# QSPI register map
Vendor: Texas Instruments
Peripheral module from a debugger description file (folder am574x).
Registers are 32-bit, access per field, reset 0x0 unless marked. A register's access mark holds for its fields unless they carry their own. Offsets are as the file gives them; lines under a group give offsets from that group; [hi:lo] are bit positions; {n}, {i} and the like mark numbered series; 'fields as' and 'values as' point back to an identical list; <NAME> marks a mode.

## QSPI
0x00 QSPI_PID ro reset not defined — Revision register
  [31:0] REVISION — IP Revision
0x10 QSPI_SYSCONFIG reset 0x28
  [3:2] IDLE_MODE rw — Configuration of the local target state management mode. By definition, target can handle read/write transaction as long as it is out of IDLE state. 0x0: Force-idle mode 0x1: No-idle mode 0x2: Smart-idle mode 0x3: Reserved.
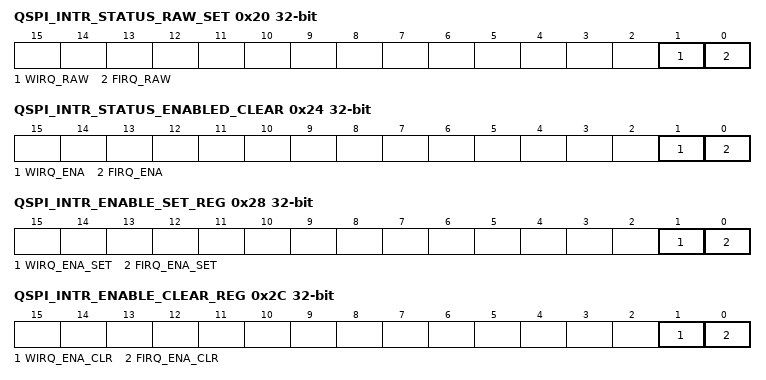
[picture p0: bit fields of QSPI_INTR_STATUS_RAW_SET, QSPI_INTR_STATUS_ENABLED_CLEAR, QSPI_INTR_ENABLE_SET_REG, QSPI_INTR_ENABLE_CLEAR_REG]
0x20 QSPI_INTR_STATUS_RAW_SET rw — This register contains raw interrupt status flags.
  [1] WIRQ_RAW — Word Interrupt Status. Read indicates the raw status.Read: . Write: .
    0=READ_INACTIVE (No interrupt); 1=READ_ACTIVE (Interrupt); 0=READ_INACTIVE (Has no effect); 1=READ_ACTIVE (Sets this raw status bit)
  [0] FIRQ_RAW — Frame Interrupt Status. Read indicates the raw status.Read: . Write: .
    0=READ_INACTIVE (No interrupt); 1=READ_ACTIVE (Interrupt); 0=Has_no_effect; 1=Sets_this_raw_status_bit
0x24 QSPI_INTR_STATUS_ENABLED_CLEAR — This register contains status flags of the enabled interrupts.
  [1] WIRQ_ENA rw — Word Interrupt Enabled Status. Read indicates enabled status.Read: . Write: .
    0=INACTIVE (No interrupt); 1=ACTIVE (Interrupt); 0=INACTIVE (Has no effect); 1=ACTIVE (Clears the word interrupt status flag. The corresponding raw status flag is also cleared.)
  [0] FIRQ_ENA rw — Frame Interrupt Enabled Status. Read indicates enabled status.Read: . Write: .
    0=INACTIVE (No interrupt); 1=ACTIVE (Interrupt); 0=INACTIVE (Has no effect); 1=ACTIVE (Clears the frame interrupt status flag. The corresponding raw status flag is also cleared.)
0x28 QSPI_INTR_ENABLE_SET_REG — This register enables the interrupts.
  [1] WIRQ_ENA_SET rw — Word interrupt enable.Read: . Write: .
    0=Disabled (Word interrupt is disabled); 1=Enabled (Word interrupt enabled); 0=Has_no_effect; 1=Enables_the_word_interrupt
  [0] FIRQ_ENA_SET rw — Frame interrupt enable.Read: . Write: .
    0=Disabled (Frame interrupt is disabled); 1=Enabled (Frame interrupt is enabled); 0=Has_no_effect; 1=Enables_the_frame_interrupt
0x2C QSPI_INTR_ENABLE_CLEAR_REG — This register disables the interrupts.
  [1] WIRQ_ENA_CLR rw — Word interrupt disable.Read: . Write: .
    0=Disabled (Word interrupt is disabled); 1=Enabled (Word interrupt is enabled); 0=Has_no_effect; 1=Clears_the_word_interrupt
  [0] FIRQ_ENA_CLR rw — Frame interrupt disable.Read: . Write: .
    0=Disabled (Frame interrupt is disabled); 1=Enabled (Frame interrupt is enabled); 0=Has_no_effect; 1=Clears_the_frame_interrupt
0x30 QSPI_INTC_EOI_REG rw — Software End-Of-Interrupt: Allows the generation of further pulses on the interrupt line, if a new interrupt event is pending, when using the pulsed output. Unused when using the level interrupt line (depending on module integration).
  [31:0] EOI_VECTOR — Number associated with the interrupt outputs. There is one interrupt output. Write 0x0 after servicing the interrupt to be able to generate another interrupt if pulse interrupts are used. Any other write value is ignored.
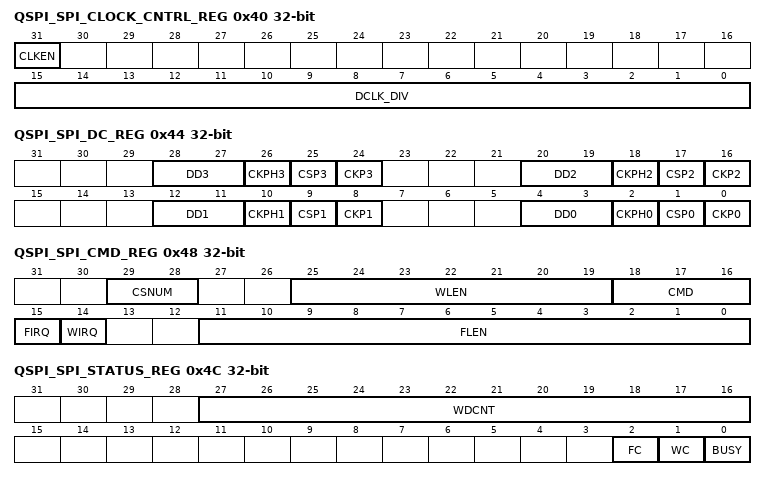
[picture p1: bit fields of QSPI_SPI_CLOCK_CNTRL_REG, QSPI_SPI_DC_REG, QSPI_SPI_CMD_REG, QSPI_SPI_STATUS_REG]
0x40 QSPI_SPI_CLOCK_CNTRL_REG — This register controls the external SPI clock generation. This register can only be written when the QSPI module is not busy, as identified by the[0] BUSY bit.
  [31] CLKEN rw — External SPI clock (qspi1_sclk) enable.
    0=DCLOCK_OFF (The qspi1_sclk clock is turned off); 1=DCLOCK_ON (The qspi1_sclk clock is enabled)
  [15:0] DCLK_DIV rw — Divide ratio for the external SPI clock (qspi1_sclk)
0x44 QSPI_SPI_DC_REG — This register controls the different modes for each output chip select. This register can only be written when the QSPI module is not busy, as identified by the[0] BUSY bit.
  [8n+4:8n+3] DD{n} rw (n=0..3) — Data delay for chip select {n} 0x0: Data is output on the same cycle as the qspi1_cs[{n}] goes active 0x1: Data is output 1 qspi1_sclk cycle after the qspi1_cs[{n}] goes active 0x2: Data is output 2 qspi1_sclk cycles after the qspi1_cs[{n}] goes active 0x3: Data is output 3 qspi1_sclk cycles after the qspi1_cs[{n}] goes active
  [8n+2] CKPH{n} rw (n=0..3) — Clock phase for chip select {n}. If CKP{n} = 0: 0x0: Data shifted out on falling edge; input on 0x1: Data shifted out on rising edge; input on If CKP{n} = 1: 0x0: Data shifted out on rising edge; input on 0x1: Data shifted out on falling edge; input on
  [8n+1] CSP{n} rw (n=0..3) — Chip select polarity for chip select {n}.
    0=ACTIVE_LOW; 1=ACTIVE_HIGH
  [8n] CKP{n} rw (n=0..3) — Clock polarity for chip select {n}.
    0=NO_DATA_DCLK_0 (When there are no data transfers the qspi1_sclk is '0'); 1=NO_DATA_DCLK_1 (When there are no data transfers the qspi1_sclk is '1')
0x48 QSPI_SPI_CMD_REG — This register sets up the SPI command. This register can only be written when the QSPI module is not busy, as identified by the[0] BUSY bit.
  [29:28] CSNUM rw — Device select. Sets the active chip select for the current transfer. 0x0: Chip Select 0 active 0x1: Chip Select 1 active 0x2: Chip Select 2 active 0x3: Chip Select 3 active
  [25:19] WLEN rw — Word length. Sets the size of the individual transfers from 1 to 128 bits. When a word length greater than 32 bits is configured, not only the 0x0: 1 bit 0x1: 2 bits ... 0x7F: 128 bits
  [18:16] CMD rw — Transfer command. 0x0: Reserved 0x1: 4-pin Read Single 0x2: 4-pin Write Single 0x3: 4-pin Read Dual 0x4: Reserved 0x5: 3-pin Read Single 0x6: 3-pin Write Single 0x7: 6-pin Read Quad
  [15] FIRQ rw — Frame complete interrupt enable.
    0=FRAME_COUNT_IRQ_DISABLE (The interrupt is disabled); 1=FRAME_COUNT_IRQ_ENABLE (The interrupt is enabled)
  [14] WIRQ rw — Word complete interrupt enable
    0=WORD_COUNT_IRQ_DISABLE (The interrupt is disabled); 1=WORD_COUNT_IRQ_ENABLE (The interrupt is enabled)
  [11:0] FLEN rw — Frame Length. 0x0: 1 word 0x1: 2 words ... 0xFFF: 4096 words
0x4C QSPI_SPI_STATUS_REG ro — This register contains indicators to allow the user to monitor the progression of a frame transfer. This register can only be written when the QSPI module is not busy, as identified by the[0] BUSY bit.
  [27:16] WDCNT — Word count. This field will reflect the 1-4096 words transferred
  [2] FC — Frame complete. This bit is set after the transmision of all the requested words completes. This bit is reset whenQSPI_SPI_STATUS_REG register is read.
    0=FRAME_TRANSFER_NOT_COMPLETE (Transfer is not complete); 1=FRAME_TRANSFER_COMPLETE (Transfer is complete)
  [1] WC — Word complete. This bit is set after each word transfer completes. This bit is reset whenQSPI_SPI_STATUS_REG register is read.
    0=WORD_TRANSFER_NOT_COMPLETE (Word transfer is not complete); 1=WORD_TRANSFER_COMPLETE (Word transfer is complete)
  [0] BUSY — Busy bit. Active transfer in progress. This bit is only set during an active word transfer. Between words it is cleared.
    0=IDLE; 1=BUSY
0x50 QSPI_SPI_DATA_REG rw — The data received in this register is shifted to the LSB position and the content of the register is shifted to the left. This register acts as the first 32-bit register of the 128-bit shift in/out register. This register is cleared between reads or writes and can only be written when the QSPI module is not busy, as identified by the[0] BUSY bit.
  [31:0] DATA — Data register for read and write operations
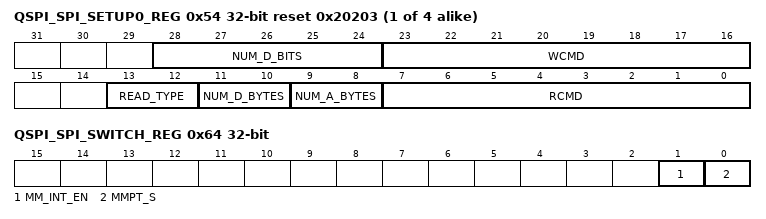
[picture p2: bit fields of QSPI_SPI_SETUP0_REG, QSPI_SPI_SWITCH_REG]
{0x54+4i} QSPI_SPI_SETUP{i}_REG reset 0x20203 (i=0..3) — This register contains the read/write command setup for the memory mapped protocol translator (effecting chip select {i} output). By default (reset), the device uses a write command of 2, read command of 3 and address bytes number of 3. This default covers most of the serial flash devices, but can be changed.
  [28:24] NUM_D_BITS rw — Number of dummy bits to use if NUM_D_BYTES = 0x0
  [23:16] WCMD rw — Write command
  [13:12] READ_TYPE rw — Determines if the read command is a single, dual or quad read mode command. 0x0: Normal read (all data input on qspi1_d[1]) 0x1: Dual read (odd bytes input on qspi1_d[1]; even bytes on qspi1_d[0]) 0x2: Normal read (all data input on qspi1_d[1]) 0x3: Quad read (uses also qspi1_d[2] and qspi1_d[3])
  [11:10] NUM_D_BYTES rw — Number of dummy bytes to be used for fast read. 0x0: No dummy bytes required. Use the value in NUM_D_BITS 0x1: Use 8 bits 0x2: Use 16 bits 0x3: Use 24 bits
  [9:8] NUM_A_BYTES rw — Number of address bytes to be sent. 0x0: 1 byte 0x1: 2 bytes 0x2: 3 bytes 0x3: 4 bytes
  [7:0] RCMD rw — Read Command
0x64 QSPI_SPI_SWITCH_REG — This register allows initiators to switch control of the SPI core port between the configuration port and the SFI translator. In addition, an interrupt enable field is defined which is used to enable or disable word complete interrupt generation in memory mapped mode.
  [1] MM_INT_EN rw — Memory mapped mode interrupt enable.
    0=MM_MODE_INTR_DISABLED (Word complete interrupt is disabled during memory mapped operations); 1=MM_MODE_INTR_ENABLED (Word complete interrupt is enabled for memory mapped operations)
  [0] MMPT_S rw — MPT select.
    0=SEL_CFG_PORT (Configuration port is selected to control the SPI_CORE.); 1=SEL_MM_PORT (SFI translator is selected to control the SPI_CORE.)
0x68 QSPI_SPI_DATA_REG_1 rw — The data received in this register is shifted to the LSB position and the content of the register is shifted to the left. This register acts as the second 32-bit register of the 128-bit shift in/out register. This register is cleared between reads or writes and can only be written when the QSPI module is not busy, as identified by the[0] BUSY bit.
  [31:0] DATA — Data register for read and write operations
0x6C QSPI_SPI_DATA_REG_2 rw — The data received in this register is shifted to the LSB position and the content of the register is shifted to the left. This register acts as the third 32-bit register of the 128-bit shift in/out register. This register is cleared between reads or writes and can only be written when the QSPI module is not busy, as identified by the[0] BUSY bit.
  [31:0] DATA — Data register for read and write operations
0x70 QSPI_SPI_DATA_REG_3 rw — The data received in this register is shifted to the LSB position and the content of the register is shifted to the left. This register acts as the fourth 32-bit register of the 128-bit shift in/out register. This register is cleared between reads or writes and can only be written when the QSPI module is not busy, as identified by the[0] BUSY bit.
  [31:0] DATA — Data register for read and write operations
